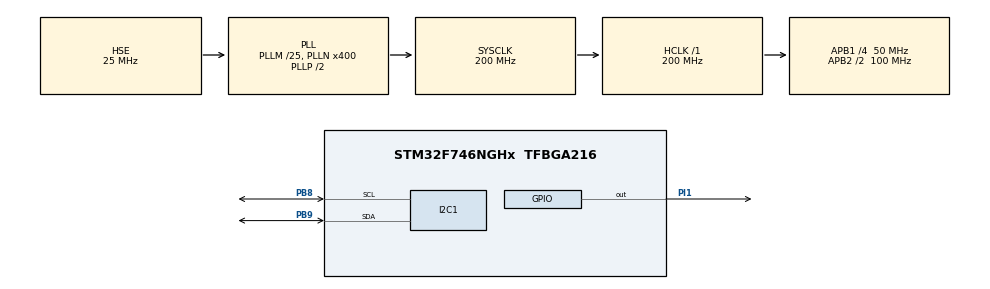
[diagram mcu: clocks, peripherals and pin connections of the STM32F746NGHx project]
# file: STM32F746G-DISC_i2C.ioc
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I2C1.Timing=0x00C0EAFF
Mcu.Family=STM32F7
Mcu.Name=STM32F746NGHx
Mcu.Package=TFBGA216
NVIC.PriorityGroup=NVIC_PRIORITYGROUP_4
NVIC.TIM1_UP_TIM10_IRQn=true\:15\:0\:false\:false\:true\:false\:true
NVIC.TimeBase=TIM1_UP_TIM10_IRQn
NVIC.TimeBaseIP=TIM1
PA13.Mode=Serial_Wire
PA13.Signal=SYS_JTMS-SWDIO
PA14.Mode=Serial_Wire
PA14.Signal=SYS_JTCK-SWCLK
PB8.GPIO_Pu=GPIO_PULLUP
PB8.Mode=I2C
PB8.Signal=I2C1_SCL
PB9.GPIO_Pu=GPIO_PULLUP
PB9.Mode=I2C
PB9.Signal=I2C1_SDA
PH0/OSC_IN.Mode=HSE-External-Oscillator
PH0/OSC_IN.Signal=RCC_OSC_IN
PH1/OSC_OUT.Mode=HSE-External-Oscillator
PH1/OSC_OUT.Signal=RCC_OSC_OUT
PI1.Signal=GPIO_Output
ProjectManager.HeapSize=0x200
ProjectManager.StackSize=0x400
ProjectManager.TargetToolchain=STM32CubeIDE
RCC.AHBFreq_Value=200000000
RCC.APB1CLKDivider=RCC_HCLK_DIV4
RCC.APB1Freq_Value=50000000
RCC.APB1TimFreq_Value=100000000
RCC.APB2CLKDivider=RCC_HCLK_DIV2
RCC.APB2Freq_Value=100000000
RCC.APB2TimFreq_Value=200000000
RCC.CortexFreq_Value=200000000
RCC.HCLKFreq_Value=200000000
RCC.HSE_VALUE=25000000
RCC.HSI_VALUE=16000000
RCC.LSE_VALUE=32768
RCC.PLL48CLockSelection=RCC_CLK48SOURCE_PLLSAIP
RCC.PLLI2SN=100
RCC.PLLM=25
RCC.PLLN=400
RCC.PLLQ=9
RCC.PLLSAIN=384
RCC.PLLSAIP=RCC_PLLSAIP_DIV8
RCC.PLLSAIR=5
RCC.PLLSAIRDiv=RCC_PLLSAIDIVR_8
RCC.PLLSourceVirtual=RCC_PLLSOURCE_HSE
RCC.SDMMCClockSelection=RCC_SDMMC1CLKSOURCE_CLK48
RCC.SYSCLKFreq_VALUE=200000000
RCC.SYSCLKSource=RCC_SYSCLKSOURCE_PLLCLK
RCC.USBFreq_Value=48000000
RCC.VCOOutputFreq_Value=400000000
VP_SYS_VS_tim1.Mode=TIM1
board=STM32F746G-DISCO

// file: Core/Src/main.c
/* USER CODE BEGIN Header */
/**
  ******************************************************************************
  * @file           : main.c
  * @brief          : Main program body
  ******************************************************************************
  * @attention
  *
  * <h2><center>&copy; Copyright (c) 2021 STMicroelectronics.
  * All rights reserved.</center></h2>
  *
  * This software component is licensed by ST under Ultimate Liberty license
  * SLA0044, the "License"; You may not use this file except in compliance with
  * the License. You may obtain a copy of the License at:
  *                             www.st.com/SLA0044
  *
  ******************************************************************************
  */
/* USER CODE END Header */
#include "main.h"

/* USER CODE BEGIN Includes */
#include "lcd16x2_i2c.h"
/* USER CODE END Includes */

I2C_HandleTypeDef hi2c1;

void SystemClock_Config(void);
static void MX_GPIO_Init(void);
static void MX_I2C1_Init(void);

int main(void)
{

  /* MCU Configuration--------------------------------------------------------*/

  /* Reset of all peripherals, Initializes the Flash interface and the Systick. */
  HAL_Init();

  /* Configure the system clock */
  SystemClock_Config();

  /* Initialize all configured peripherals */
  MX_GPIO_Init();
  MX_I2C1_Init();
  /* USER CODE BEGIN 2 */
 if(lcd16x2_i2c_init(&hi2c1)){
	 HAL_GPIO_WritePin(GPIOI, GPIO_PIN_1, 1);
 }
 lcd16x2_i2c_clear();

  /* USER CODE END 2 */

  /* Infinite loop */
  /* USER CODE BEGIN WHILE */
 int a = 400;
  while (1)
  {

	  lcd16x2_i2c_setCursor(0,0);
	  lcd16x2_i2c_printf("T: %.2f",1.23);
	  lcd16x2_i2c_setCursor(0,9);
	  lcd16x2_i2c_printf("D: %.2f",1.24);
	  lcd16x2_i2c_setCursor(1,0);
	  lcd16x2_i2c_printf("H: %.2f",11.26);
	  lcd16x2_i2c_setCursor(1,9);
	  lcd16x2_i2c_printf("C: %d",a);
	  a++;

	  HAL_Delay(1000);
	  /* USER CODE END WHILE */

  }
}

void SystemClock_Config(void)
{
  RCC_OscInitTypeDef RCC_OscInitStruct = {0};
  RCC_ClkInitTypeDef RCC_ClkInitStruct = {0};
  RCC_PeriphCLKInitTypeDef PeriphClkInitStruct = {0};

  /** Configure the main internal regulator output voltage
  */
  __HAL_RCC_PWR_CLK_ENABLE();
  __HAL_PWR_VOLTAGESCALING_CONFIG(PWR_REGULATOR_VOLTAGE_SCALE1);
  /** Initializes the RCC Oscillators according to the specified parameters
  * in the RCC_OscInitTypeDef structure.
  */
  RCC_OscInitStruct.OscillatorType = RCC_OSCILLATORTYPE_HSE;
  RCC_OscInitStruct.HSEState = RCC_HSE_ON;
  RCC_OscInitStruct.PLL.PLLState = RCC_PLL_ON;
  RCC_OscInitStruct.PLL.PLLSource = RCC_PLLSOURCE_HSE;
  RCC_OscInitStruct.PLL.PLLM = 25;
  RCC_OscInitStruct.PLL.PLLN = 400;
  RCC_OscInitStruct.PLL.PLLP = RCC_PLLP_DIV2;
  RCC_OscInitStruct.PLL.PLLQ = 9;
  if (HAL_RCC_OscConfig(&RCC_OscInitStruct) != HAL_OK)
  {
    Error_Handler();
  }
  /** Activate the Over-Drive mode
  */
  if (HAL_PWREx_EnableOverDrive() != HAL_OK)
  {
    Error_Handler();
  }
  /** Initializes the CPU, AHB and APB buses clocks
  */
  RCC_ClkInitStruct.ClockType = RCC_CLOCKTYPE_HCLK|RCC_CLOCKTYPE_SYSCLK
                              |RCC_CLOCKTYPE_PCLK1|RCC_CLOCKTYPE_PCLK2;
  RCC_ClkInitStruct.SYSCLKSource = RCC_SYSCLKSOURCE_PLLCLK;
  RCC_ClkInitStruct.AHBCLKDivider = RCC_SYSCLK_DIV1;
  RCC_ClkInitStruct.APB1CLKDivider = RCC_HCLK_DIV4;
  RCC_ClkInitStruct.APB2CLKDivider = RCC_HCLK_DIV2;

  if (HAL_RCC_ClockConfig(&RCC_ClkInitStruct, FLASH_LATENCY_6) != HAL_OK)
  {
    Error_Handler();
  }
  PeriphClkInitStruct.PeriphClockSelection = RCC_PERIPHCLK_I2C1;
  PeriphClkInitStruct.I2c1ClockSelection = RCC_I2C1CLKSOURCE_PCLK1;
  if (HAL_RCCEx_PeriphCLKConfig(&PeriphClkInitStruct) != HAL_OK)
  {
    Error_Handler();
  }
}

static void MX_I2C1_Init(void)
{

  hi2c1.Instance = I2C1;
  hi2c1.Init.Timing = 0x00C0EAFF;
  hi2c1.Init.OwnAddress1 = 0;
  hi2c1.Init.AddressingMode = I2C_ADDRESSINGMODE_7BIT;
  hi2c1.Init.DualAddressMode = I2C_DUALADDRESS_DISABLE;
  hi2c1.Init.OwnAddress2 = 0;
  hi2c1.Init.OwnAddress2Masks = I2C_OA2_NOMASK;
  hi2c1.Init.GeneralCallMode = I2C_GENERALCALL_DISABLE;
  hi2c1.Init.NoStretchMode = I2C_NOSTRETCH_DISABLE;
  if (HAL_I2C_Init(&hi2c1) != HAL_OK)
  {
    Error_Handler();
  }
  /** Configure Analogue filter
  */
  if (HAL_I2CEx_ConfigAnalogFilter(&hi2c1, I2C_ANALOGFILTER_ENABLE) != HAL_OK)
  {
    Error_Handler();
  }
  /** Configure Digital filter
  */
  if (HAL_I2CEx_ConfigDigitalFilter(&hi2c1, 0) != HAL_OK)
  {
    Error_Handler();
  }

}

static void MX_GPIO_Init(void)
{
  GPIO_InitTypeDef GPIO_InitStruct = {0};

  /* GPIO Ports Clock Enable */
  __HAL_RCC_GPIOB_CLK_ENABLE();
  __HAL_RCC_GPIOA_CLK_ENABLE();
  __HAL_RCC_GPIOI_CLK_ENABLE();
  __HAL_RCC_GPIOH_CLK_ENABLE();

  /*Configure GPIO pin Output Level */
  HAL_GPIO_WritePin(GPIOI, GPIO_PIN_1, GPIO_PIN_RESET);

  /*Configure GPIO pin : PI1 */
  GPIO_InitStruct.Pin = GPIO_PIN_1;
  GPIO_InitStruct.Mode = GPIO_MODE_OUTPUT_PP;
  GPIO_InitStruct.Pull = GPIO_NOPULL;
  GPIO_InitStruct.Speed = GPIO_SPEED_FREQ_LOW;
  HAL_GPIO_Init(GPIOI, &GPIO_InitStruct);

}

void HAL_TIM_PeriodElapsedCallback(TIM_HandleTypeDef *htim)
{
  if (htim->Instance == TIM1) {
    HAL_IncTick();
  }
}

void Error_Handler(void)
{
  __disable_irq();
  while (1)
  {
  }
}

/************************ (C) COPYRIGHT STMicroelectronics *****END OF FILE****/
